# USB0_VBP2AHB_WRAP_CONTROLLER_VBP_USB3_CORE_GBL register map
Vendor: Texas Instruments
Peripheral module from a debugger description file (folder am62P).
Registers are 32-bit, read-write, reset 0x0 unless marked. A register's access mark holds for its fields unless they carry their own. Offsets are as the file gives them; lines under a group give offsets from that group; [hi:lo] are bit positions; {n}, {i} and the like mark numbered series; 'fields as' and 'values as' point back to an identical list; <NAME> marks a mode.

## USB0_VBP2AHB_WRAP_CONTROLLER_VBP_USB3_CORE_GBL (part 1 of 4)
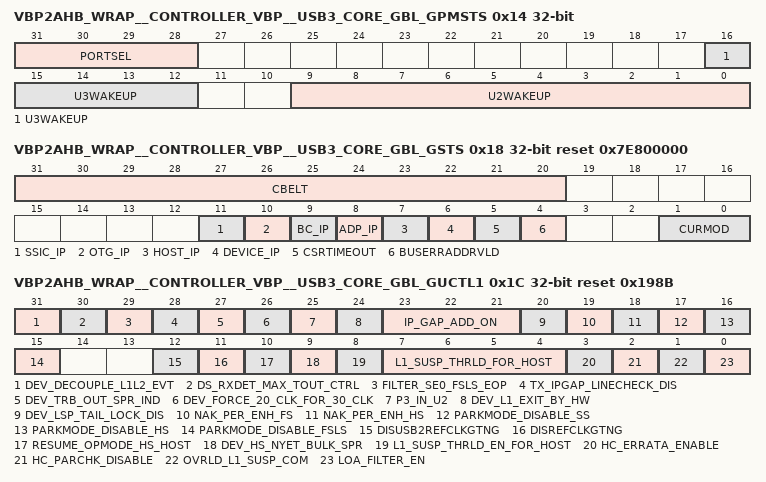
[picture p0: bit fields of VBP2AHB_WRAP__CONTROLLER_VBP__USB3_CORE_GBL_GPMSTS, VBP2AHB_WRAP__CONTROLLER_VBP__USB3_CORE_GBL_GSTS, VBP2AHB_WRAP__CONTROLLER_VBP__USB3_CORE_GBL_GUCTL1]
0x14 VBP2AHB_WRAP__CONTROLLER_VBP__USB3_CORE_GBL_GPMSTS access per field — Global Power Management Status Register This debug register gives information on which event caused the hibernation exit. It provides internal status and state machine information, and is for Synopsys use only for debugging purposes. This register is not applicable in USB 2.0-only mode.
  [31:28] PORTSEL wo — Global Power Management Status Register, PortSel This field selects the port number.
  [16:12] U3WAKEUP ro — U3Wakeup This field gives the following USB 3.0 port wakeup conditions: - Bit [12]: Overcurrent Detected - Bit [13]: Resume Detected - Bit [14]: Connect Detected - Bit [15]: Disconnect Detected - Bit [16]: Last Connection State
  [9:0] U2WAKEUP ro — U2Wakeup This field indicates the following USB 2.0 port wakeup conditions: - Bit [0]: Overcurrent Detected - Bit [1]: Resume Detected - Bit [2]: Connect Detected - Bit [3]: Disconnect Detected - Bit [4]: Last Connection State - Bit [5]: ID Change Detected - Bit [6]: SRP Request Detected - Bit [7]: ULPI Interrupt Detected - Bit [8]: USB Reset Detected - Bit [9]: Resume Detected Changed
0x18 VBP2AHB_WRAP__CONTROLLER_VBP__USB3_CORE_GBL_GSTS access not given reset 0x7E800000 — Global Status Register
  [31:20] CBELT ro — Current BELT Value In Host mode, this field indicates the minimum value of all received device BELT values and the BELT value that is set by the Set Latency Tolerance Value command.
  [11] SSIC_IP ro — This field is not used.
  [10] OTG_IP ro — This field is not used.
  [9] BC_IP ro — Battery Charger Interrupt Pending This field indicates that there is a pending interrupt pertaining to BC in BCEVT register.
  [8] ADP_IP ro — This field is not used.
  [7] HOST_IP ro — Host Interrupt Pending: This field indicates that there is a pending interrupt pertaining to xHC in the Host event queue.
  [6] DEVICE_IP ro — Device Interrupt Pending This field indicates that there is a pending interrupt pertaining to peripheral [device] operation in the Device event queue.
  [5] CSRTIMEOUT — CSR Timeout When this bit is 1'b1, it indicates that the software performed a write or read to a controller register that could not be completed within DWC_USB3_CSR_ACCESS_TIMEOUT bus clock cycles [default: h1FFFF]. (access R/W1TC)
  [4] BUSERRADDRVLD — Bus Error Address Valid [BusErrAddrVld] Indicates that the GBUSERRADDR register is valid and reports the first bus address that encounters a bus error. Note: Only supported in AHB and AXI configurations. (access R/W1TC)
  [1:0] CURMOD ro — Current Mode of Operation [CurMod] Indicates the current mode of operation: - 2'b00: Device mode - 2'b01: Host mode
0x1C VBP2AHB_WRAP__CONTROLLER_VBP__USB3_CORE_GBL_GUCTL1 access per field reset 0x198B — Global User Control Register 1
  [31] DEV_DECOUPLE_L1L2_EVT rw — DEV_DECOUPLE_L1L2_EVT - 0: Default behavior, no change in device events L1/L2U3 events are not decoupled [old behavior of v2.90a and before] - 1: Feature enabled, L1 and L2 events are separated when operating in 2.0 mode. Separate event enable bits for L1 suspend and wake events. This bit is applicable for device mode only. If this feature is enabled, L1 suspend and wake events have individual controls to enable/mask them. Enable this feature if you want to get L1 [LPM] events separtely and not combined with L2 events when operating in 2.0 speeds.
  [30] DS_RXDET_MAX_TOUT_CTRL rw — DS_RXDET_MAX_TOUT_CTRL This bit is used to control the tRxDetectTimeoutDFP timer for the SuperSpeed link. - 0: Default behavior. 12ms is used as tRxDetectTimeoutDFP. - 1: 120ms is used as the tRxDetectTimeoutDFP. This bit is used only in host mode. For more details, refer to ECN020 for USB 3.0 Specification.
  [29] FILTER_SE0_FSLS_EOP rw — FILTER_SE0_FSLS_EOP - 0: Default behavior, no change in Linestate check for SE0 detection in FS/LS - 1: Feature enabled, FS/LS SE0 is filtered for 2 clocks for detecting EOP This bit is applicable for FS/LS operation. If this feature is enabled, then SE0 on the linestate is validated for 2 consecutive utmi/ulpi clock edges for EOP detection. This feature is applicable only in FS in device mode and FS/LS mode of operation in host mode. Device mode: FS - If GUCTL1.FILTER_SE0_FSLS_EOP is set, then for device LPM handshake, the controller will ignore single SE0 glitch on the linestate during transmit. Only 2 or more SE0 is considered as a valid EOP on FS. Host mode: FS/LS - If GUCTL1.FILTER_SE0_FSLS_EOP is set, then the controller will ignore single SE0 glitch on the linestate during transmit. Only 2 or more SE0 is considered as a valid EOP on FS/LS port. Enable this feature if the LineState has SE0 glitches during transmission. This bit is quasi-static, that is, it must not be changed during device operation.
  [28] TX_IPGAP_LINECHECK_DIS rw — TX_IPGAP_LINECHECK_DIS - 0: Default behavior, no change in Linestate check - 1: Feature enabled, 2.0 MAC disables Linestate check during HS transmit This bit is applicable for HS operation of u2mac. If this feature is enabled, then the 2.0 mac operating in HS ignores the UTMI/ULPI Linestate during the transmit of a token [during token-to-token and token-to-data IPGAP]. When enabled, the controller implements a fixed 40-bit TxEndDelay after the packet is given on UTMI and ignores the Linestate during this time. This feature is applicable only in HS mode of operation. Device mode: If GUCTL1.TX_IPGAP_LINECHECK_DIS is set, then for device LPM handshake, the controller will ignore the linestate after TX and wait for fixed clocks [40 bit times equivalent] after transmitting ACK on utmi. Host mode: If GUCTL1.TX_IPGAP_LINECHECK_DIS is set, then the ipgap between [tkn to tkn/data] is added by 40 bit times of TXENDDELAY, and linestate is ignored during this 40 bit times delay. Enable this bit if the LineState will not reflect the expected line state [J] during transmission. This bit is quasi-static, that is, it must not be changed during device operation.
  [27] DEV_TRB_OUT_SPR_IND rw — DEV_TRB_OUT_SPR_IND - 0: Default behavior, no change in TRB status dword - 1: Feature enabled, OUT TRB status indicates Short Packet This bit is applicable for device mode only [and ignored in host mode]. If the device application [software/hardware] wants to know if a short packet was received for an OUT in the TRB status itself, then this feature can be enabled, so that a bit is set in the TRB writeback in the buf_size dword. Bit[26] - SPR of the {trbstatus, RSVD, SPR, PCM1, bufsize} dword will be set during an OUT transfer TRB write back if this is the last TRB used for that transfer descriptor. This bit is quasi-static, that is, it must not be changed during device operation.
  [26] DEV_FORCE_20_CLK_FOR_30_CLK rw — DEV_FORCE_20_CLK_FOR_30_CLK - 0: Default behavior, Uses 3.0 clock when operating in 2.0 mode - 1: Feature enabled This bit is applicable [and to be set] for device mode [DCFG.Speed != SS] only. In the 3.0 device controller, if the controller is programmed to operate in 2.0 only [that is, Device Speed is programmed to 2.0 speeds in DCFG[Speed]], then setting this bit makes the internal 2.0 [utmi/ulpi] clock to be routed as the 3.0 [pipe] clock. Enabling this feature allows the pipe3 clock to be not-running when forcibly operating in 2.0 device mode. Note: - When using this feature, all pipe3 inputs must be in inactive mode. In particular, the pipe3 clocks must not be running and the pipe3_phystatus_async must be tied to 0. This bit should not be set if the controller is programmed to operate in SuperSpeed mode [even when it falls back to 2.0]. - This bit is quasi-static, that is, it must not be changed during operation. - If the parameter DWC_USB3_REMOVE_PIPE_CLK_MUX_FOR_20_MODE is enabled, then muxing 2.0 clock/signals to pipe_clk/signals have to be done outside the controller for this feature to work.
  [25] P3_IN_U2 rw — P3_IN_U2 - 0: Default behavior, When SuperSpeed link is in U2, PowerState P2 is attempted on the PIPE Interface. - 1: When SuperSpeed link is in U2, PowerState P3 is attempted if GUSB3PIPECTL[17] is set. Setting this bit enables P3 Power State when the SuperSpeed link is in U2. Another Power Saving option. Check with your PHY vendor before enabling this option.When setting this bit to 1 to enable P3 in P2, GUSB3PIPECTL[27] should be set to 0 to make sure that the U2 exit is attempted in P0. This bit should be set only when GCTL.SOFITPSYNC=1 or GFLADJ.GFLADJ_REFCLK_LPM_SEL=1.
  [24] DEV_L1_EXIT_BY_HW rw — DEV_L1_EXIT_BY_HW - 0: Default behavior, disables device L1 hardware exit logic - 1: feature enabled This bit is applicable for device mode [2.0] only. This field enables device controller sending remote wakeup for L1 if the device becomes ready for sending/accepting data when in L1 state. If the host expects the device to send remote wakeup signaling to resume after going into L1 in flow controlled state, then this bit can be set to send the remote wake signal automatically when the device controller becomes ready. This hardware remote wake feature is applicable only to bulk and interrupt transfers, and not for Isoch/Control - When control transfers are in progress, the LPM will be rejected [NYET response]. Only after control transfers are completed [either with ACK/STALL], LPM will be accepted - For Isoch transfers, the host needs to do the wake-up and start the transfer. Device controller will not do remote-wakeup when Isoch endpoints get ready. The device SW needs to keep the GUSB2PHYCFG[EnblSlpM] reset in order to keep the PHY clock to be running for keeping track of SOF intervals. - When L1 hibernation is enabled, the controller will not do automatic exit for hibernation requests thru L1. This bit is quasi-static, that is, it must not be changed during device operation.
  [23:21] IP_GAP_ADD_ON rw — This register field is used to add on to the default inter packet gap setting in the USB 2.0 MAC. This should be programmed to a non zero value only in case where you need to increase the default inter packet delay calculations in the USB 2.0 MAC module DWC_usb3_u2mac.v
  [20] DEV_LSP_TAIL_LOCK_DIS rw — DEV_LSP_TAIL_LOCK_DIS - 0: Default behavior, enables device lsp lock logic for tail TRB update - 1: Fix disabled This is a bug fix for STAR 9000716195 that affects the CSP mode for OUT endpoints in device mode. The issue is that tail TRB index is not synchronized with the cache Scratchpad bytecount update. If the fast-forward request comes in-between the bytecount update on a newly fetched TRB and the tail-index write update in TPF, the RDP works on an incorrect tail index and misses the byte count decrement for the newly fetched TRB in the fast-forwarding process. This fix needs to be present all the times.
  [19] NAK_PER_ENH_FS rw — NAK_PER_ENH_FS - 1: Enables performance enhancement for FS async endpoints in the presence of NAKs - 0: Enhancement not applied If a periodic endpoint is present , and if a bulk endpoint which is also active is being NAKed by the device, then this could result in a decrease in performance of other Full Speed bulk endpoint which is ACked by the device. Setting this bit to 1, will enable the host controller to schedule more transactions to the async endpoints [bulk/ control] and hence will improve the performance of the bulk endpoint. This control bit should be enabled only if the existing performance with the default setting is not sufficient for your FullSpeed application. Setting this bit will only control, and is only required for Full Speed transfers.
  [18] NAK_PER_ENH_HS rw — NAK_PER_ENH_HS - 1: Enables performance enhancement for HS async endpoints in the presence of NAKs - 0: Enhancement not applied If a periodic endpoint is present, and if a bulk endpoint which is also active is being NAKed by the device, then this could result in decrease in performance of other High Speed bulk endpoint which is ACked by the device. Setting this bit to 1, will enable the host controller to schedule more transactions to the async endpoints [ bulk/ control] and hence will improve the performance of the bulk endpoint. This control bit should be enabled only if the existing performance with the default setting is not sufficient for your HighSpeed application. Setting this bit will only control, and is only required for High Speed transfers.
  [17] PARKMODE_DISABLE_SS rw — PARKMODE_DISABLE_SS This bit is used only in host mode, and is for debug purpose only. When this bit is set to '1' all SS bus instances in park mode are disabled.
  [16] PARKMODE_DISABLE_HS rw — PARKMODE_DISABLE_HS This bit is used only in host mode. When this bit is set to '1' all HS bus instances park mode are disabled. To improve performance in park mode, the xHCI scheduler queues in three requests of 4 packets each for High Speed asynchronous endpoints in a micro-frame. But if a device is slow and if it NAKs more than 3 times, then it is rescheduled only in the next micro-frame. This could decrease the performance of a slow device even further. In a few high speed devices [such as Sandisk Cruzer Blade 4GB VID:1921, PID:21863 and Flex Drive VID:3744, PID:8552] when an IN request is sent within 900ns of the ACK of the previous packet, these devices send a NAK. When connected to these devices, if required, the software can disable the park mode if you see performance drop in your system. When park mode is disabled, pipelining of multiple packet is disabled and instead one packet at a time is requested by the scheduler. This allows up to 12 NAKs in a micro-frame and improves performance of these slow devices.
  [15] PARKMODE_DISABLE_FSLS rw — PARKMODE_DISABLE_FSLS This bit is used only in host mode, and is for debug purpose only. When this bit is set to '1' all FS/LS bus instances in park mode disabled.
  [12] DISUSB2REFCLKGTNG ro — Disable ref_clk gating for 2.0 PHY [DisUSB2RefClkGtng] If ref_clk gating is disabled, then the ref_clk input cannot be turned off to the USB 2.0 PHY and controller. This is independent of the GCTL[DisClkGtng] setting. - 1'b0: ref_clk gating enabled for USB 2.0 PHY - 1'b1: ref_clk gating disabled for USB 2.0 PHY
  [11] DISREFCLKGTNG ro — Disable ref_clk gating [DisRefClkGtng] If the ref_clk gating is disabled then input ref_clk cannot be turned off to SSPHY and controller. This is independent of GCTL[DisClkGtng] setting. - 1'b0: ref_clk gating Enabled for SSPHY - 1'b1: ref_clk gating Disabled for SSPHY
  [10] RESUME_OPMODE_HS_HOST rw — RESUME_OPMODE_HS_HOST This bit is used only in host mode, and is for USB 2.0 opmode behavior in HS Resume. - When this bit is set to '1', the UTMI/ULPI opmode will be changed to normal along with HS terminations after EOR. This option is to support certain legacy UTMI/ULPI PHYs. - When this bit is set to '0', the UTMI/ULPI opmode will be changed to normal 2us after HS terminations change after EOR. This is the default behavior.
  [9] DEV_HS_NYET_BULK_SPR rw — DEV_HS_NYET_BULK_SPR - 0: Default behavior, no change in device response - 1: Feature enabled, HS bulk OUT short packet gets NYET response This bit is applicable for device mode only [and ignored in host mode] to be used in 2.0 operation. If this bit is set, the device controller sends NYET response instead of ACK response for a successfully received bulk OUT short packet. If NYET is sent after receiving short packet, then the host would PING before sending the next OUT. this improves the performance as well as clears up the buffer/cache on the host side. Internal to the device controller, short packet [SPR=1] processing takes some time, and during this time, the USB is flow controlled. With NYET response instead of ACK on short packet, the host does not send another OUT-DATA without pinging in HS mode. This bit is quasi-static, that is, it must not be changed during device operation.
  [8] L1_SUSP_THRLD_EN_FOR_HOST rw — L1_SUSP_THRLD_EN_FOR_HOST This bit is used only in host mode. The host controller asserts the utmi_l1_suspend_n and utmi_sleep_n output signals [see LPM Interface Signals table in the Databook] as follows: The controller asserts the utmi_l1_suspend_n signal to put the PHY into deep low-power mode in L1 when both of the following are true: - The HIRD/BESL value used is greater than or equal to the value in L1_SUSP_THRLD_FOR_HOST field. - The L1_SUSP_THRLD_EN_FOR_HOST bit is set to 1'b1. The controller asserts utmi_sleep_n on L1 when one of the following is true: - The HIRD/BESL value used is less than the value in L1_SUSP_THRLD_FOR_HOST field. - The L1_SUSP_THRLD_EN_FOR_HOST bit is set to 1'b0.
  [7:4] L1_SUSP_THRLD_FOR_HOST rw — L1_SUSP_THRLD_FOR_HOST This field is effective only when the L1_SUSP_THRLD_EN_FOR_HOST bit is set to 1. For more details, refer to the description of the L1_SUSP_THRLD_EN_FOR_HOST bit.
  [3] HC_ERRATA_ENABLE rw — Host ELD Enable [HELDEn] When this bit is set to 1, it enables the Exit Latency Delta [ELD] support defined in the xHCI 1.0 Errata. This bit is used only in the host mode. This bit has to be set to 1 in Host mode.
  [2] HC_PARCHK_DISABLE rw — Host Parameter Check Disable [HParChkDisable] When this bit is set to '0' [by default], the xHC checks that the input slot/EP context fields comply to the xHCI Specification. Upon detection of a parameter error during command execution, the xHC generates an event TRB with completion code indicating 'PARAMETER ERROR'. When the bit is set to '1', the xHC does not perform parameter checks and does not generate 'PARAMETER ERROR' completion code.
  [1] OVRLD_L1_SUSP_COM rw — OVRLD_L1_SUSP_COM If this bit is set, the utmi_l1_suspend_com_n is overloaded with the utmi_sleep_n signal. This bit is usually set if the PHY stops the port clock during L1 sleep condition. Note: The recommended connection for the SUSPENDM/SLEEPM signals to the PHY with respect to this bit is as follows. For non-zero ports: Connect: - utmi_sleep_n[n] to SLEEPM[n] - [utmi_suspend_n[n] & utmi_l1_suspend_n[n]] to SUSPENDM[n] - USB2 PHYCLK[n] to utmi_clk[n] GUCTL1.OVRLD_L1_SUSP_COM impacts only Port0. For Port0: For Synopsys PHY, GUSB2PHYCFGn.U2_FREECLK_EXISTS=1. With this connection, the PHY keeps PLL active so that FREECLK is always available irrespective of suspend/sleep. - Connect USB2 PHY COMMONONN to 0. - Connect utmi_sleep_n[0] to SLEEPM[0]. - Connect [utmi_suspend_n[0] & utmi_l1_suspend_n[0]] to SUSPENDM[0]. - Connect USB2 PHY FREECLK to utmi_clk[0]. - Leave utmi_suspend_com_n, utmi_l1_suspend_com_n unconnected. - GUCTL1.OVRLD_L1_SUSP_COM can be set to any value. For Third Party PHY, GUSB2PHYCFGn.U2_FREECLK_EXISTS=0. With this connection the PHY can shut off all the clocks when the required conditions are met [like, GUSB2PHYCFGn[8,6], GUCTL1[1], GFLADJ[23], GCTL[10], Suspend condition, HW LPM enable etc]. - Connect -utmi_suspend_com_n to SUSPENDM[0] [or equivalent]. - Connect -utmi_l1_suspend_com_n to SLEEPM[0] [or equivalent]. - Connect PHYCLK0 [first port clock] to utmi_clk[0]. - Leave utmi_suspend_n[0], utmi_l1_suspend_ n[0], utmi_sleep_n[0] unconnected. - Set GUCTL1.OVRLD_L1_SUSP_COM to 1'b1.
  [0] LOA_FILTER_EN rw — LOA_FILTER_EN If this bit is set, the USB 2.0 port babble is checked at least three consecutive times before the port is disabled. This prevents false triggering of the babble condition when using low quality cables. Note: This bit is valid only in host mode.
